# RA register map
Vendor: Renesas; Series: All Chips; File version: x.xx
Registers are 32-bit, read-write, reset 0x0 unless marked. A register's access mark holds for its fields unless they carry their own. Offsets are from the block's base; [hi:lo] are bit positions; {n}, {i} and the like mark numbered series.

## R_DALI0 — Digital Addressable Lighting Interface
Base 0x4008F000
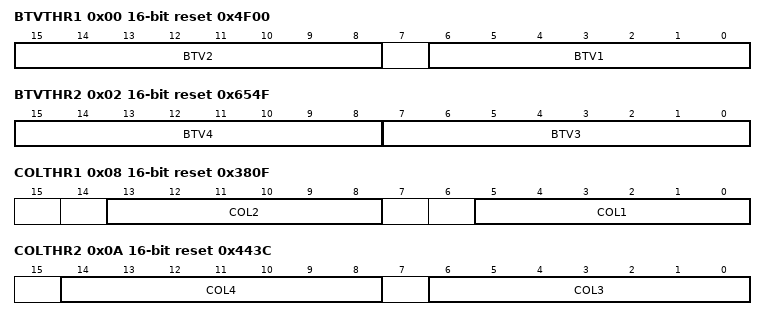
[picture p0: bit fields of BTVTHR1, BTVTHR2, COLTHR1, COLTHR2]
0x00 BTVTHR1 16-bit reset 0x4F00 — DALI Bit Timing Violation Threshold Register 1
  [15:8] BTV2 — Bit Timing Violation Threshold 2Specifies the bit timing violation threshold value 2.Note 1. These bits must be modified when the DALI0.CTR1.RE bit is 0 and the DALI0.CTR1.TE bit is 0.
  [6:0] BTV1 — Bit Timing Violation Threshold 1Specifies the bit timing violation threshold value 1.Note 1. These bits must be modified when the DALI0.CTR1.RE bit is 0 and the DALI0.CTR1.TE bit is 0.
0x02 BTVTHR2 16-bit reset 0x654F — DALI Bit Timing Violation Threshold Register 2
  [15:8] BTV4 — Bit Timing Violation Threshold 4Specifies the bit timing violation threshold value 4.Note 1. These bits must be modified when the DALI0.CTR1.RE bit is 0 and the DALI0.CTR1.TE bit is 0.
  [7:0] BTV3 — Bit Timing Violation Threshold 3Specifies the bit timing violation threshold value 3.Note 1. These bits must be modified when the DALI0.CTR1.RE bit is 0 and the DALI0.CTR1.TE bit is 0.
0x04 BTVTHR3 16-bit reset 0x9D — DALI Bit Timing Violation Threshold Register 3
  [7:0] BTV5 — Bit Timing Violation Threshold 5Specifies the bit timing violation threshold value 5.Note 1. These bits must be modified when the DALI0.CTR1.RE bit is 0 and the DALI0.CTR1.TE bit is 0.
0x06 BTVTHR4 16-bit reset 0xDB — DALI Bit Timing Violation Threshold Register 4
  [8:0] BTV6 — Bit Timing Violation Threshold 6Specifies the bit timing violation threshold value 6.Note 1. These bits must be modified when the DALI0.CTR1.RE bit is 0 and the DALI0.CTR1.TE bit is 0.
0x08 COLTHR1 16-bit reset 0x380F — DALI Collision Threshold Register 1
  [13:8] COL2 — Collision Threshold 2Specifies the collision threshold value 2.Note 1. These bits must be modified when the DALI0.CTR1.RE bit is 0 and the DALI0.CTR1.TE bit is 0.
  [5:0] COL1 — Collision Threshold 1Specifies the collision threshold value 1.Note 1. These bits must be modified when the DALI0.CTR1.RE bit is 0 and the DALI0.CTR1.TE bit is 0.
0x0A COLTHR2 16-bit reset 0x443C — DALI Collision Threshold Register 2
  [14:8] COL4 — Collision Threshold 4Specifies the collision threshold value 4.Note 1. These bits must be modified when the DALI0.CTR1.RE bit is 0 and the DALI0.CTR1.TE bit is 0.
  [6:0] COL3 — Collision Threshold 3Specifies the collision threshold value 3.Note 1. These bits must be modified when the DALI0.CTR1.RE bit is 0 and the DALI0.CTR1.TE bit is 0.
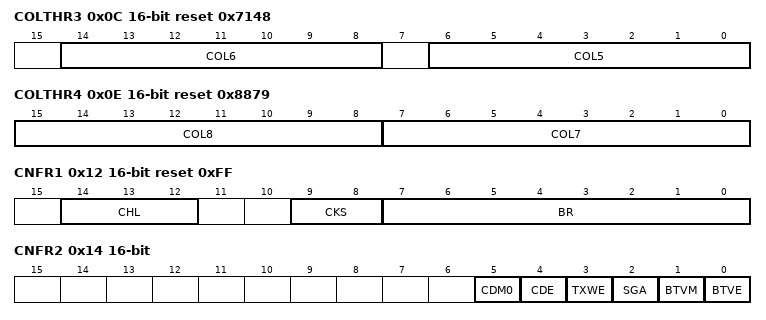
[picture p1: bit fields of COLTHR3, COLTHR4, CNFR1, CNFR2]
0x0C COLTHR3 16-bit reset 0x7148 — DALI Collision Threshold Register 3
  [14:8] COL6 — Collision Threshold 6Specifies the collision threshold value 6.Note 1. These bits must be modified when the DALI0.CTR1.RE bit is 0 and the DALI0.CTR1.TE bit is 0.
  [6:0] COL5 — Collision Threshold 5Specifies the collision threshold value 5.Note 1. These bits must be modified when the DALI0.CTR1.RE bit is 0 and the DALI0.CTR1.TE bit is 0.
0x0E COLTHR4 16-bit reset 0x8879 — DALI Collision Threshold Register 4
  [15:8] COL8 — Collision Threshold 8Specifies the collision threshold value 8.Note 1. These bits must be modified when the DALI0.CTR1.RE bit is 0 and the DALI0.CTR1.TE bit is 0.
  [7:0] COL7 — Collision Threshold 7Specifies the collision threshold value 7.Note 1. These bits must be modified when the DALI0.CTR1.RE bit is 0 and the DALI0.CTR1.TE bit is 0.
0x10 COLTHR5 16-bit reset 0x8E — DALI Collision Threshold Register 5
  [7:0] COL9 — Collision Threshold 9Specifies the collision threshold value 9.Note 1. These bits must be modified when the DALI0.CTR1.RE bit is 0 and the DALI0.CTR1.TE bit is 0.
0x12 CNFR1 16-bit reset 0xFF — DALI Configuration Register 1
  [14:12] CHL — Character Length
    0=8 bits; 1=16 bits; 2=24 bits; 3=32 bits; 4=20 bits; 5=17 bits; other=others (Setting prohibited)
  [9:8] CKS — Clock Select
    0=PCLK clock (x = 0); 1=PCLK/4 clock (x = 1); 2=PCLK/16 clock (x = 2); 3=PCLK/64 clock (x = 3)
  [7:0] BR — Clock SelectBit rate setting example is shown in Table
0x14 CNFR2 16-bit — DALI Configuration Register 2
  [5] CDM0 — Collision Detect ModeNote: The bit must be modified only when the DALI0.STR1.BBF bit is 0.
    0=Destroy area; 1=Destroy area and avoidance area (edge)
  [4] CDE — Collision Detect EnableNote: The bit must be modified only when the DALI0.STR1.BBF bit is 0.
    0=Collision detection is disabled; 1=Collision detection is enabled
  [3] TXWE — DTX Width Modulation EnableNote: The bit must be modified only when the DALI0.STR1.BBF bit is 0.
    0=The width of DTX0 waveform is not modulated; 1=The width of DTX0 waveform is modulated
  [2] SGA — Save an Edge of Gray Area ModeNote: The bit must be modified only when the DALI0.STR1.BBF bit is 0.
    0=The edge allowable area of the DRX0 input signal is the default; 1=The edge allowable area of the DRX0 input signal is extended
  [1] BTVM — Bit Timing Violation ModeNote: The bit must be modified only when the DALI0.STR1.BBF bit is 0.
    0=Edge in gray area between half bit and 2-half bit is not detected as bit timing violation; 1=Edge in gray area between half bit and 2-half bit is detected as bit timing violation
  [0] BTVE — Bit Timing Violation EnableNote: The bit must be modified only when the DALI0.STR1.BBF bit is 0.
    0=Bit timing violation function is disabled; 1=Bit timing violation function is enabled
0x16 TXWR1 16-bit reset 0x3F — DALI DTX Width Register 1
  [6:0] TXLW — DTX Low WidthDTX0 pin low level width
0x1E TDR1H 16-bit — DALI Transmit Data Register 1H
  [15:0] DTDR — Upper 16-bit DALI transmit data
0x20 TDR1L 16-bit — DALI Transmit Data Register 1L
  [15:0] DTDR — Lower 16-bit DALI transmit data
0x22 TRSTR1 16-bit wo (alternate view of SPDR) — DALI Transmit Control Register 1
  [0] TRST — Transmission Start Trigger
    0=No effect; 1=Transmission Start
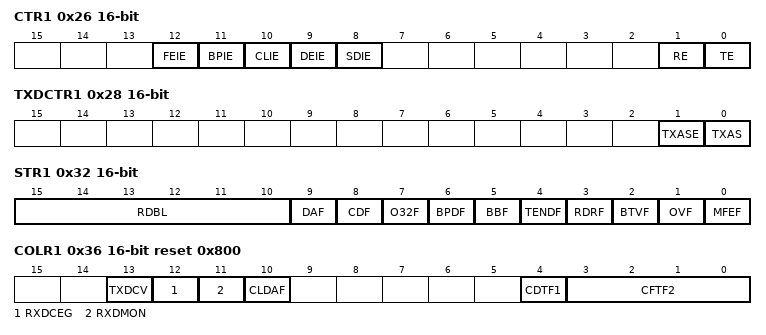
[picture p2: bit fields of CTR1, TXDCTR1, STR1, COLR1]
0x26 CTR1 16-bit — DALI Control Register 1
  [12] FEIE — DALI_FEI Output Enabling
    0=DALI_FEI output is disabled; 1=DALI_FEI output is enabled
  [11] BPIE — DALI_BPI Output Enabling
    0=DALI_BPI output is disabled; 1=DALI_BPI output is enabled
  [10] CLIE — DALI_CLI Output Enabling
    0=DALI_CLI output is disabled; 1=DALI_CLI output is enabled
  [9] DEIE — DALI_DEI Output Enabling
    0=DALI_DEI output is disabled; 1=DALI_DEI output is enabled
  [8] SDIE — DALI_SDI Output Enabling
    0=DALI_SDI output is disabled; 1=DALI_SDI output is enabled
  [1] RE — Receive Enabling
    0=Storing received data is disabled; 1=Storing received data is enabled
  [0] TE — Transmit Enabling
    0=Transmit operation is disabled; 1=Transmit operation is enabled
0x28 TXDCTR1 16-bit — DALI DTX Control Register 1
  [1] TXASE — DTX Assert EnablingNote 1. The bit must be modified only when the DALI0.CTR1.TE bit is 0.
    0=An internal transmit data is output to the DTX0 pin; 1=The level specified by TXAS bit is output to the DTX0 pin
  [0] TXAS — DTX Assert LevelNote 1. The bit must be modified only when the DALI0.CTR1.TE bit is 0.
    0=The DTX0 pin is driven low; 1=The DTX0 pin is driven high
0x2E RDR1H 16-bit ro — DALI Reception Data Register 1H
  [15:0] DRDR — Upper 16-bit of DALI receive data
0x30 RDR1L 16-bit ro — DALI Reception Data Register 1L
  [15:0] DRDR — Lower 16-bit of DALI receive data
0x32 STR1 16-bit ro — DALI Status Register 1
  [15:10] RDBL — Receive Data Bit LengthThese bits store the bit length for data received successfully
  [9] DAF — Destroy Area Flag
    0=The collision did not occur in the destroy area or 1 was written to the DALI0.FECR1.DAFC bit; 1=The collision occurred in the destroy area
  [8] CDF — Collision Detect Flag
    0=No collision occurred or 1 was written to the DALI0.FECR1.CDFC bit; 1=A collision occurred
  [7] O32F — Over 32-Bit Data Reception Flag
    0=Receive data is 32 bits or less, or 1 was written to the DALI0.FECR1.O32FC bit; 1=Receive data is 33 bits or more
  [6] BPDF — Bus Power Down Flag
    0=No effected; 1=Bus power down detected
  [5] BBF — Bus BUSY Flag
    0=DALI bus is IDLE; 1=DALI bus is BUSY
  [4] TENDF — Transmit End Flag
    0=1 was written to the DALI0.FECR1.TENDFC bit; 1=Frame transmission has been completed
  [3] RDRF — Receive Data Register Full Flag
    0=The DALI0.RDR1L register was read or 1 was written to the DALI0.FECR1.RDRFC; 1=Receive data is stored in the DALI0.RDR1L or DALI0.RDR1H register
  [2] BTVF — Bit Timing Violation Flag
    0=No bit timing violation occurred or 1 was written to the DALI0.FECR1.BTVFC bit; 1=Bit timing violation occurred
  [1] OVF — Overrun Error Flag
    0=No overrun error occurred or 1 was written to the DALI0.FECR1.OVFC bit; 1=An overrun error occurred
  [0] MFEF — Manchester Flaming Error Flag
    0=No MFE occurred or 1 was written to the DALI0.FECR1.MFEFC bit; 1=An MFE occurred
0x36 COLR1 16-bit ro reset 0x800 — DALI Collision Register 1
  [13] TXDCV — DTX Collision Value
    0=Low; 1=High
  [12] RXDCEG — DRX Collision Edge
    0=Falling edge; 1=Rising edge
  [11] RXDMON — DRX MonitorThis bit monitors the DRX0 pin value after the DRX0 pin is synchronized
  [10] CLDAF — Collision Last Destroy Area Flag
    0=Collision detected is caused by a DRX0 edge occurrence; 1=Collision detected is not caused by a DRX0 edge occurrence. (Last destroy area)
  [4] CDTF1 — Collision Detect Timing Flag 1
    0=Collision detection started at the edge on a bit period boundary; 1=Collision detection started at the edge in the middle of a bit period
  [3:0] CFTF2 — Collision Detect Timing Flag 2
    0=After reset is released; {v}=Collision detection timing {v} (v=1..6); {v}=Collision detection timing {v} *1 (v=7..10); other=others (Setting prohibited)
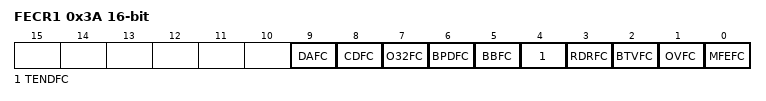
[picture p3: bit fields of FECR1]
0x3A FECR1 16-bit wo — DALI Flag Error Clear Register 1
  [9] DAFC — Destroy Area Flag Clear
    0=DALI0.STR1.DAF bit is not cleared; 1=DALI0.STR1.DAF bit is cleared
  [8] CDFC — Collision Detect Flag Clear
    0=DALI0.STR1.CDF bit is not cleared; 1=DALI0.STR1.CDF bit is cleared
  [7] O32FC — Over 32-Bit Data Reception Flag Clear
    0=DALI0.STR1.O32F bit is not cleared; 1=DALI0.STR1.O32F bit is cleared
  [6] BPDFC — Bus Power Down Flag Clear
    0=DALI0.STR1.BPDF bit is not cleared; 1=DALI0.STR1.BPDF bit is cleared
  [5] BBFC — Bus BUSY Flag ClearNote1: Do not clear DALI0.STR1.BBF bit when DALI0.CTR1.TE bit or DALI0.CTR1.RE bit is 1.
    0=DALI0.STR1.BBF bit is not cleared; 1=DALI0.STR1.BBF bit is cleared
  [4] TENDFC — Transmit End Flag Clear
    0=DALI0.STR1.TENDF bit is not cleared; 1=DALI0.STR1.TENDF bit is cleared
  [3] RDRFC — Receive Data Register Full Flag Clear
    0=DALI0.STR1.RDRF bit is not cleared; 1=DALI0.STR1.RDRF bit is cleared
  [2] BTVFC — Bit Timing Violation Flag Clear
    0=DALI0.STR1.BTVF bit is not cleared; 1=DALI0.STR1.BTVF bit is cleared
  [1] OVFC — Overrun Error Flag Clear
    0=DALI0.STR1.OVF bit is not cleared; 1=DALI0.STR1.OVF bit is cleared
  [0] MFEFC — Manchester Flaming Error Flag Clear
    0=DALI0.STR1.MFEF bit is not cleared; 1=DALI0.STR1.MFEF bit is cleared
0x3C SWRR1 16-bit wo — DALI Software Reset Register 1
  [0] SWR — Software ResetWriting 1 to this bit causes a software reset.
